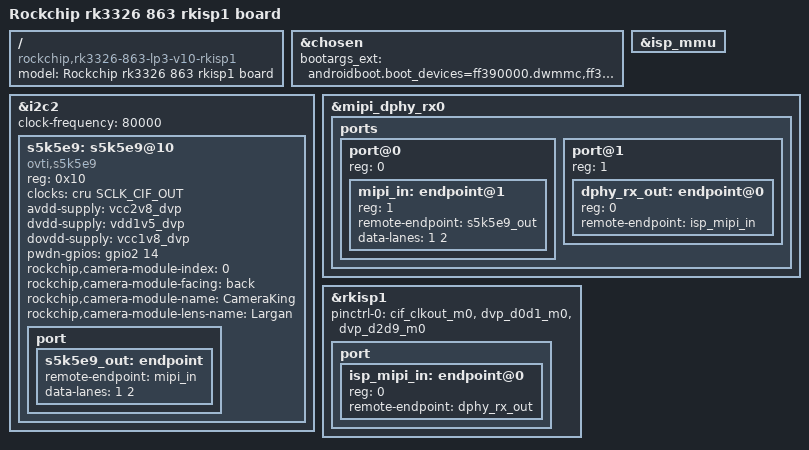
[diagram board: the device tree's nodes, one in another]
// SPDX-License-Identifier: (GPL-2.0+ OR MIT)
/*
 * Copyright (c) 2019 Fuzhou Rockchip Electronics Co., Ltd
 */

/dts-v1/;
#include "rk3326-863-lp3-v10.dtsi"

/ {
	model = "Rockchip rk3326 863 rkisp1 board";
	compatible = "rockchip,rk3326-863-lp3-v10-rkisp1", "rockchip,rk3326";
};

&chosen {
	bootargs_ext = "androidboot.boot_devices=ff390000.dwmmc,ff3b0000.nandc";
};

&i2c2 {
	status = "okay";
   clock-frequency = <80000>;
	s5k5e9: s5k5e9@10 {
		status = "okay";
		compatible = "ovti,s5k5e9";
		reg = <0x10>;
		//pinctrl-names = "default";
		//pinctrl-0 = <&cif_clkout_m0>;

		clocks = <&cru SCLK_CIF_OUT>;
		clock-names = "xvclk";

		avdd-supply = <&vcc2v8_dvp>;
		dvdd-supply = <&vdd1v5_dvp>;
		dovdd-supply = <&vcc1v8_dvp>;
		pwdn-gpios = <&gpio2 14 GPIO_ACTIVE_HIGH>;
		rockchip,camera-module-index = <0>;
		rockchip,camera-module-facing = "back";
		rockchip,camera-module-name = "CameraKing";
		rockchip,camera-module-lens-name = "Largan";
		port {
			s5k5e9_out: endpoint {
				remote-endpoint = <&mipi_in>;
				data-lanes = <1 2>;
			};
		};
	};
};

&isp_mmu {
	status = "okay";
};
&mipi_dphy_rx0 {
	status = "okay";

	ports {
		#address-cells = <1>;
		#size-cells = <0>;

		port@0 {
			reg = <0>;
			#address-cells = <1>;
			#size-cells = <0>;

			mipi_in: endpoint@1 {
				reg = <1>;
				remote-endpoint = <&s5k5e9_out>;
				data-lanes = <1 2>;
			};
		};

		port@1 {
			reg = <1>;
			#address-cells = <1>;
			#size-cells = <0>;

			dphy_rx_out: endpoint@0 {
				reg = <0>;
				remote-endpoint = <&isp_mipi_in>;
			};
		};
	};
};

&rkisp1 {
	status = "okay";
	pinctrl-names = "default";
	pinctrl-0 = <&cif_clkout_m0 &dvp_d0d1_m0 &dvp_d2d9_m0>;

	port {
		#address-cells = <1>;
		#size-cells = <0>;

			isp_mipi_in: endpoint@0 {
				reg = <0>;
				remote-endpoint = <&dphy_rx_out>;
			};

	};
};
